# T113-S3 register map
Vendor: Allwinner; Series: T113-S3; File version: 0.1
CPU: other 0, little endian, MPU, no FPU, 0 interrupt priority bits
Registers are 32-bit, read-write, reset 0x0 unless marked. A register's access mark holds for its fields unless they carry their own. Offsets are from the block's base; [hi:lo] are bit positions; 'fields as' and 'values as' point back to an identical list.

## Timer
Base 0x02050000
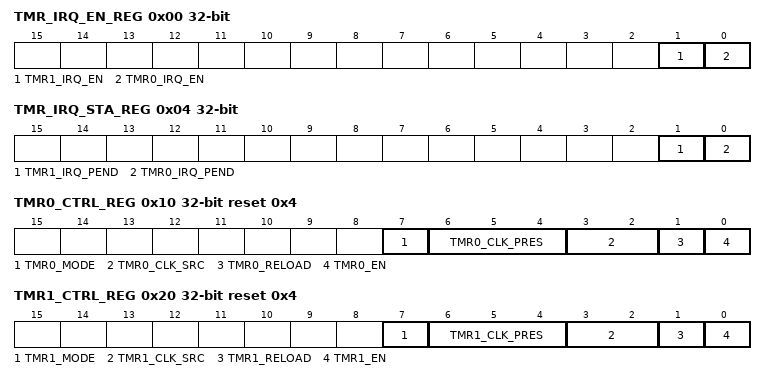
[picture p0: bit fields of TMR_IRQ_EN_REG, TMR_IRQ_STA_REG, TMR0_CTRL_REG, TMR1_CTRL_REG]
0x00 TMR_IRQ_EN_REG — Timer IRQ Enable Register
  [1] TMR1_IRQ_EN — Timer1 Interrupt Enable 0: Disabled 1: Enabled
    0=Disabled; 1=Enabled
  [0] TMR0_IRQ_EN — Timer0 Interrupt Enable 0: Disabled 1: Enabled
    0=Disabled; 1=Enabled
0x04 TMR_IRQ_STA_REG — Timer Status Register
  [1] TMR1_IRQ_PEND write-1-clears — The IRQ pending bit for Timer1 0: No effect 1: Pending, indicates that the interval value of the timer 1 is reached. Write 1 to clear the pending status.
    0=No_effect; 1=Pending, indicates that the interval value of the timer 1 is reached. Write 1 to clear the pending status.
  [0] TMR0_IRQ_PEND write-1-clears — The IRQ pending bit for Timer0 0: No effect 1: Pending, indicates that the interval value of the timer 0 is reached. Write 1 to clear the pending status.
    0=No_effect; 1=Pending, indicates that the interval value of the timer 0 is reached. Write 1 to clear the pending status.
0x10 TMR0_CTRL_REG reset 0x4 — Timer0 Control Register
  [7] TMR0_MODE — Select the timing mode for timer0 0: Periodic mode. When the interval value of the timer 0 is reached, the timer will restart another round of counting automatically. 1: Single counting mode. When the interval value of the timer 0 is reached, the timer will stop counting.
    0=Periodic mode. When the interval value of the timer 0 is reached, the timer will restart another round of counting automatically.; 1=Single counting mode. When the interval value of the timer 0 is reached, the timer will stop counting.
  [6:4] TMR0_CLK_PRES — Select the pre-scale of timer0 clock source 000: /1 001: /2 010: /4 011: /8 100: /16 101: /32 110: /64 111: /128
    0=_slash_1 (/1); 1=_slash_2 (/2); 2=_slash_4 (/4); 3=_slash_8 (/8); 4=_slash_16 (/16); 5=_slash_32 (/32); 6=_slash_64 (/64); 7=_slash_128 (/128)
  [3:2] TMR0_CLK_SRC — Select the clock source for timer0 00: LOSC 01: OSC24M 10: / 11: /
    0=LOSC; 1=OSC24M
  [1] TMR0_RELOAD — Timer0 Reload 0: No effect 1: Reload the Interval value for timer0 After the bit is set, it can not be written again before it is cleared automatically.
    0=No_effect; 1=Reload the Interval value for timer0 After the bit is set, it can not be written again before it is cleared automatically
  [0] TMR0_EN — Timer0 Enable 0: Stop/Pause 1: Start By setting the bit to 1, the timer will be started. It reloads the interval value register and then counts from the interval value to 0. By setting the bit to 0 before the timer counts to 0, the timer will be paused. The bit will be locked to 0 for at least 2 cycles. Within the 2 cycles, you cannot set the bit to 1 to restart the timer. The timer supports updating the interval value in the pause state. To start to down-count from the updated interval value, set both the reload bit and enable bit to 1. Additionally, in the single counting mode, after the count value reaches 0, the system will automatically change the bit to 0 to stop the timer.
    0=Stop_slash_Pause (Stop/Pause); 1=Start By setting the bit to 1, the timer will be started. It reloads the interval value register and then counts from the interval value to 0. By setting the bit to 0 before the timer counts to 0, the timer will be paused. The bit will be locked to 0 for at least 2 cycles. Within the 2 cycles, you cannot set the bit to 1 to restart the timer. The timer supports updating the interval value in the pause state. To start to down-count from the updated interval value, set both the reload bit and enable bit to 1. Additionally, in the single counting mode, after the count value reaches 0, the system will automatically change the bit to 0 to stop the timer.
0x14 TMR0_INTV_VALUE_REG — Timer0 Interval Value Register
  [31:0] TMR0_INTV_VALUE — Timer0 Interval Value
0x18 TMR0_CUR_VALUE_REG — Timer0 Current Value Register
  [31:0] TMR0_CUR_VALUE — Timer0 Current Value Timer0 current value is a 32-bit down-counter (from interval value to 0).
0x20 TMR1_CTRL_REG reset 0x4 — Timer1 Control Register
  [7] TMR1_MODE — Select the timing mode for timer1 0: Periodic mode. When the interval value of the timer 1 is reached, the timer will restart another round of counting automatically. 1: Single counting mode. When the interval value of the timer 1 is reached, the timer will stop counting.
    0=Periodic mode. When the interval value of the timer 1 is reached, the timer will restart another round of counting automatically.; 1=Single counting mode. When the interval value of the timer 1 is reached, the timer will stop counting.
  [6:4] TMR1_CLK_PRES — Select the pre-scale of timer1 clock source 000: /1 001: /2 010: /4 011: /8 100: /16 101: /32 110: /64 111: /128
    values as TMR0_CTRL_REG.TMR0_CLK_PRES
  [3:2] TMR1_CLK_SRC — Select the pre-scale of timer1 clock source 00: LOSC 01: OSC24M 10: / 11: /
    0=LOSC; 1=OSC24M
  [1] TMR1_RELOAD — Timer1 Reload 0: No effect 1: Reload the interval value for timer1 After the bit is set, it can not be written again before it is cleared automatically.
    0=No_effect; 1=Reload the interval value for timer1 After the bit is set, it can not be written again before it is cleared automatically
  [0] TMR1_EN — Timer1 Enable 0: Stop/Pause 1: Start By setting the bit to 1, the timer will be started. It reloads the interval value register and then counts from the interval value to 0. By setting the bit to 0 before the timer counts to 0, the timer will be paused. The bit will be locked to 0 for at least 2 cycles. Within the 2 cycles, you cannot set the bit to 1 to restart the timer. The timer supports updating the interval value in the pause state. To start to down-count from the updated interval value, set both the reload bit and enable bit to 1. Additionally, in the single counting mode, after the count value reaches 0, the system will automatically change the bit to 0 to stop the timer.
    values as TMR0_CTRL_REG.TMR0_EN
0x24 TMR1_INTV_VALUE_REG — Timer1 Interval Value Register
  [31:0] TMR1_INTV_VALUE — Timer1 Interval Value
0x28 TMR1_CUR_VALUE_REG — Timer1 Current Value Register
  [31:0] TMR1_CUR_VALUE — Timer1 Current Value Timer1 current value is a 32-bit down-counter (from interval value to 0).
0xA0 WDOG_IRQ_EN_REG — Watchdog IRQ Enable Register
  [0] WDOG_IRQ_EN — Watchdog Interrupt Enable 0: Disabled 1: Enabled
    0=Disabled; 1=Enabled
0xA4 WDOG_IRQ_STA_REG — Watchdog Status Register
  [0] WDOG_IRQ_PEND write-1-clears — The IRQ pending bit for the watchdog Write 1 to clear the pending status. 0: No effect 1: Pending, indicates that the interval value of the watchdog is reached.
    0=No_effect; 1=Pending, indicates that the interval value of the watchdog is reached
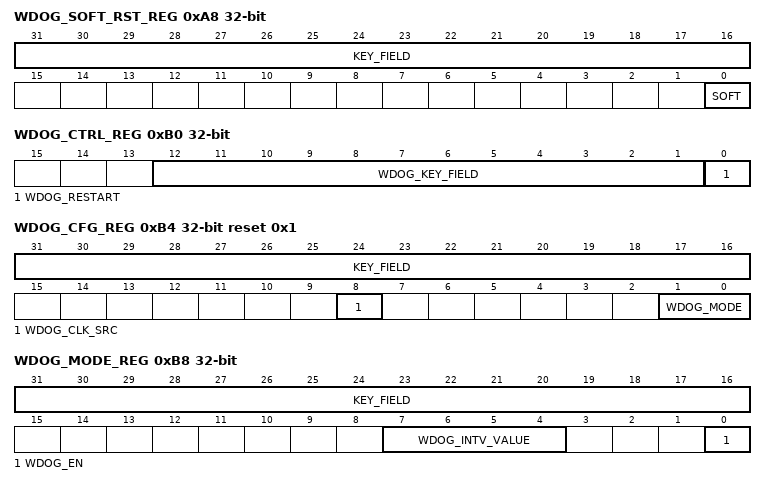
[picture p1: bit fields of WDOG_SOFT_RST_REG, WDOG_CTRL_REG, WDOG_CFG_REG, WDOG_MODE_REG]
0xA8 WDOG_SOFT_RST_REG — Watchdog Software Reset Register
  [31:16] KEY_FIELD wo — Key Field To change the value of bit[0], this field should be filled with 0x16AA.
  [0] SOFT write-1-clears — Soft Reset Enable 0: De-assert 1: Reset the system
    0=deassert; 1=Reset the system
0xB0 WDOG_CTRL_REG — Watchdog Control Register
  [12:1] WDOG_KEY_FIELD wo — Watchdog Key Field It should be written to 0xA57. Writing any other value in this field aborts the write operation.
  [0] WDOG_RESTART write-1-sets — Watchdog Restart 0: No effect 1: Restart the watchdog
    0=No_effect; 1=Restart the watchdog
0xB4 WDOG_CFG_REG reset 0x1 — Watchdog Configuration Register
  [31:16] KEY_FIELD wo — Key Field To change the value of bit[15:0], this field should be filled with 0x16AA.
  [8] WDOG_CLK_SRC — Select the clock source for the watchdog. 0: HOSC_32K, that is, OSC24M/750. It is a 32 KHz clock divided from the OSC24M. 1: LOSC_32K. A clock provided by the LOSC.
    0=HOSC_32K (HOSC_32K, that is, OSC24M/750. It is a 32 KHz clock divided from the OSC24M.); 1=LOSC_32K (LOSC_32K. A clock provided by the LOSC.)
  [1:0] WDOG_MODE — Configure the operating mode for the watchdog 00: / 01: To whole system 10: Only interrupt mode 11: /
    1=To whole system; 2=Only interrupt mode
0xB8 WDOG_MODE_REG — Watchdog Mode Register
  [31:16] KEY_FIELD wo — Key Field To change the value of bit[15:0], this field should be filled with 0x16AA.
  [7:4] WDOG_INTV_VALUE — Watchdog Interval Value 0000: 16000 cycles (0.5 s) 0001: 32000 cycles (1 s) 0010: 64000 cycles (2 s) 0011: 96000 cycles (3 s) 0100: 128000 cycles (4 s) 0101: 160000 cycles (5 s) 0110: 192000 cycles (6 s) 0111: 256000 cycles (8 s) 1000: 320000 cycles (10 s) 1001: 384000 cycles (12 s) 1010: 448000 cycles (14 s) 1011: 512000 cycles (16 s) Others: Reserved Note: The corresponding clock cycles for the interval value (IV) depends on the frequency of the clock: Cycles = F * IV. For example, to get a interval value of 0.5 second, if the clock source is HOSC_32K (whose frequency is 32 KHz), the cycle number is 16,000; if the clock source is LOSC_32K (whose frequency is 32.768 kHz), the cycle number is 16,384.
    0=16000 cycles (0.5 s); 1=32000 cycles (1 s); 2=64000 cycles (2 s); 3=96000 cycles (3 s); 4=128000 cycles (4 s); 5=160000 cycles (5 s); 6=192000 cycles (6 s); 7=256000 cycles (8 s); 8=320000 cycles (10 s); 9=384000 cycles (12 s); 10=448000 cycles (14 s); 11=512000 cycles (16 s) Others: Reserved Note: The corresponding clock cycles for the interval value (IV) depends on the frequency of the clock: Cycles = F * IV. For example, to get a interval value of 0.5 second, if the clock source is HOSC_32K (whose frequency is 32 KHz), the cycle number is 16,000; if the clock source is LOSC_32K (whose frequency is 32.768 kHz), the cycle number is 16,384.
  [0] WDOG_EN — Watchdog Enable 0: No effect 1: Enable the Watchdog
    0=No_effect; 1=Enable the Watchdog
0xBC WDOG_OUTPUT_CFG_REG reset 0x1F — Watchdog Output Configuration Register
  [11:0] WDOG — OUTPUT CONFIG Configure the valid time for the watchdog reset signal. T = 1/32ms*(N + 1) The default value is 1 ms.
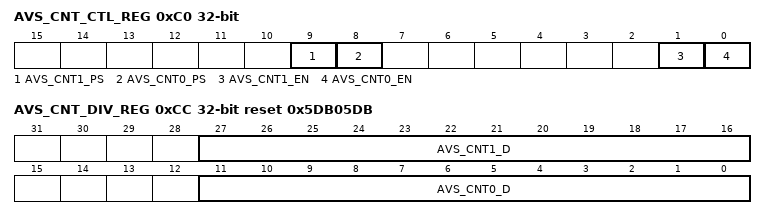
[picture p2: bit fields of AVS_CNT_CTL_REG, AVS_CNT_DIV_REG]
0xC0 AVS_CNT_CTL_REG — AVS Control Register
  [9] AVS_CNT1_PS — Audio/Video Sync Counter 1 Pause Control 0: Do not pause. 1: Pause the AVS counter1.
    0=Do_not_pause; 1=Pause the AVS counter1
  [8] AVS_CNT0_PS — Audio/Video Sync Counter 0 Pause Control 0: Do not pause. 1: Pause the AVS counter0.
    0=Do_not_pause; 1=Pause the AVS counter0
  [1] AVS_CNT1_EN — Audio/Video Sync Counter 1 Enable/Disable The clock source is OSC24M. 0: Disabled 1: Enabled
    0=Disabled; 1=Enabled
  [0] AVS_CNT0_EN — Audio/Video Sync Counter 0 Enable/Disable The clock source is OSC24M. 0: Disabled 1: Enabled
    0=Disabled; 1=Enabled
0xC4 AVS_CNT0_REG — AVS Counter 0 Register
  [31:0] AVS_CNT0 — The higher 32 bits of AVS counter0. AVS counter0 is a 33-bit up counter. The initial value consists of two parts: this register forms the bit[32:1] of AVS counter0 and the bit[0] is zero. You can set the initial value of the AVS counter0 by software. The initial value can be updated at anytime. You can also pasuse the counter by setting AVS_CNT0_PS to `1`. The counter value will not increase when it is paused.
0xC8 AVS_CNT1_REG — AVS Counter 1 Register
  [31:0] AVS_CNT1 — The higher 32 bits of AVS counter1. AVS counter1 is a 33-bit up counter. The initial value consists of two parts: this register forms the bit[32:1] of AVS counter0 and the bit[0] is zero. You can set the initial value of the AVS counter1 by software. The initial value can be updated at anytime. You can also pasuse the counter by setting AVS_CNT1_PS to `1`. The counter value will not increase when it is paused.
0xCC AVS_CNT_DIV_REG reset 0x5DB05DB — AVS Divisor Register
  [27:16] AVS_CNT1_D — N1, the divisor factor for AVS1. The clock for AVS1 is 24 MHz/N1. N1 = Bit[27:16] + 1. The valid value for N1 is from 1 to 0x7ff. There is an internal 12-bit counter maintained by the engine of the 33- bit AVS1. The 12-bit counter is used for counting the cycle number of the clock OSC24M. When the value of the 12-bit counter reaches N1, the internal 33-bit counter register will increase 1 and the 12-bit counter will reset to zero and restart again. You can change the value of N1 via the software at any time.
  [11:0] AVS_CNT0_D — N0, the divisor factor for AVS0. The clock for AVS0 is 24MHz/N0. N0 = Bit[11:0] + 1. The valid value for N0 is from 1 to 0x7ff. There is an internal 12-bit counter maintained by the engine of the 33- bit AVS0. The 12-bit counter is used for counting the cycle number of the clock OSC24M. When the value of the 12-bit counter reaches N0, the internal 33-bit counter register will increase 1 and the 12-bit counter will reset to zero and restart again. You can change the value of N0 via the software at any time.
